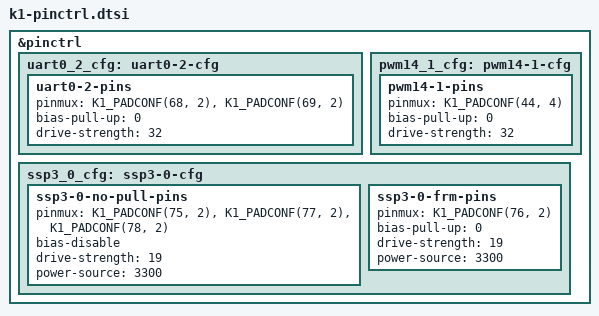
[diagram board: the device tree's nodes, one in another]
// SPDX-License-Identifier: GPL-2.0 OR MIT
/*
 * Copyright (c) 2024 Yixun Lan <dlan@gentoo.org>
 */

#include <dt-bindings/gpio/gpio.h>

#define K1_PADCONF(pin, func) (((pin) << 16) | (func))

/* Map GPIO pin to each bank's <index, offset> */
#define K1_GPIO(x)	(x / 32) (x % 32)

&pinctrl {
	uart0_2_cfg: uart0-2-cfg {
		uart0-2-pins {
			pinmux = <K1_PADCONF(68, 2)>,
				 <K1_PADCONF(69, 2)>;

			bias-pull-up = <0>;
			drive-strength = <32>;
		};
	};

	pwm14_1_cfg: pwm14-1-cfg {
		pwm14-1-pins {
			pinmux = <K1_PADCONF(44, 4)>;
			bias-pull-up = <0>;
			drive-strength = <32>;
		};
	};

	ssp3_0_cfg: ssp3-0-cfg {
		ssp3-0-no-pull-pins {
			pinmux = <K1_PADCONF(75, 2)>,	/* SCLK */
				 <K1_PADCONF(77, 2)>,	/* MOSI  */
				 <K1_PADCONF(78, 2)>;	/* MISO */

			bias-disable;
			drive-strength = <19>;
			power-source = <3300>;
		};

		ssp3-0-frm-pins {
			pinmux = <K1_PADCONF(76, 2)>;	/* FRM (frame) */

			bias-pull-up = <0>;
			drive-strength = <19>;
			power-source = <3300>;
		};
	};
};
